AUTOSAR XML (schema 00044)
package /SwComponentType
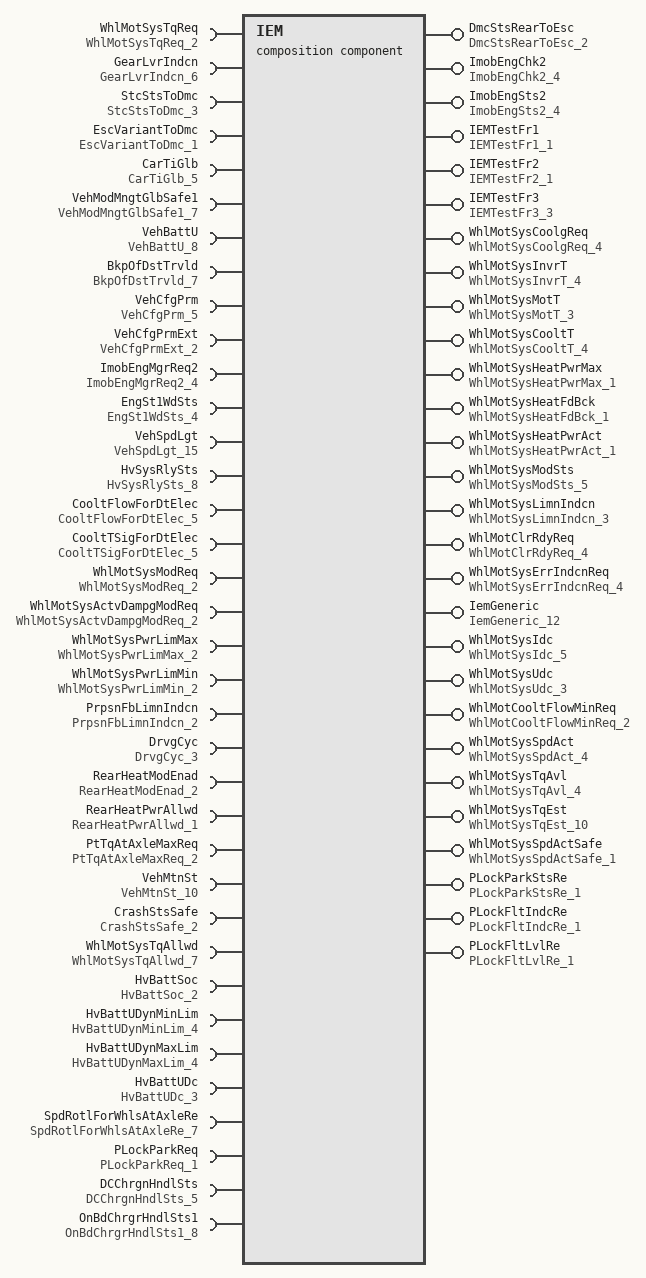
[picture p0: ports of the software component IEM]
  composition sw component type IEM
    28 x provide port:
      DmcStsRearToEsc: nonqueued-sender-com-spec{data-element=DmcStsRearToEsc, uses-end-to-end-protection=true, init-value=constant-reference=DmcStsRearToEsc_2}, provided-interface=DmcStsRearToEsc_2
      ImobEngChk2: nonqueued-sender-com-spec{data-element=ImobEngChk2, init-value=constant-reference=ImobEngChk2_4}, provided-interface=ImobEngChk2_4
      ImobEngSts2: nonqueued-sender-com-spec{data-element=ImobEngSts2, init-value=constant-reference=ImobEngSts2_4}, provided-interface=ImobEngSts2_4
      IEMTestFr1: nonqueued-sender-com-spec{data-element=IEMTestFr1, init-value=constant-reference=IEMTestFr1_1}, provided-interface=IEMTestFr1_1
      IEMTestFr2: nonqueued-sender-com-spec{data-element=IEMTestFr2, init-value=constant-reference=IEMTestFr2_1}, provided-interface=IEMTestFr2_1
      IEMTestFr3: nonqueued-sender-com-spec{data-element=IEMTestFr3, init-value=constant-reference=IEMTestFr3_3}, provided-interface=IEMTestFr3_3
      WhlMotSysCoolgReq: nonqueued-sender-com-spec{data-element=WhlMotSysCoolgReq, init-value=constant-reference=WhlMotSysCoolgReq_4}, provided-interface=WhlMotSysCoolgReq_4
      WhlMotSysInvrT: nonqueued-sender-com-spec{data-element=WhlMotSysInvrT, init-value=constant-reference=WhlMotSysInvrT_4}, provided-interface=WhlMotSysInvrT_4
      WhlMotSysMotT: nonqueued-sender-com-spec{data-element=WhlMotSysMotT, init-value=constant-reference=WhlMotSysMotT_3}, provided-interface=WhlMotSysMotT_3
      WhlMotSysCooltT: nonqueued-sender-com-spec{data-element=WhlMotSysCooltT, init-value=constant-reference=WhlMotSysCooltT_4}, provided-interface=WhlMotSysCooltT_4
      WhlMotSysHeatPwrMax: nonqueued-sender-com-spec{data-element=WhlMotSysHeatPwrMax, init-value=constant-reference=WhlMotSysHeatPwrMax_1}, provided-interface=WhlMotSysHeatPwrMax_1
      WhlMotSysHeatFdBck: nonqueued-sender-com-spec{data-element=WhlMotSysHeatFdBck, init-value=constant-reference=WhlMotSysHeatFdBck_1}, provided-interface=WhlMotSysHeatFdBck_1
      WhlMotSysHeatPwrAct: nonqueued-sender-com-spec{data-element=WhlMotSysHeatPwrAct, init-value=constant-reference=WhlMotSysHeatPwrAct_1}, provided-interface=WhlMotSysHeatPwrAct_1
      WhlMotSysModSts: nonqueued-sender-com-spec{data-element=WhlMotSysModSts, init-value=constant-reference=WhlMotSysModSts_5}, provided-interface=WhlMotSysModSts_5
      WhlMotSysLimnIndcn: nonqueued-sender-com-spec{data-element=WhlMotSysLimnIndcn, init-value=constant-reference=WhlMotSysLimnIndcn_3}, provided-interface=WhlMotSysLimnIndcn_3
      WhlMotClrRdyReq: nonqueued-sender-com-spec{data-element=WhlMotClrRdyReq, init-value=constant-reference=WhlMotClrRdyReq_4}, provided-interface=WhlMotClrRdyReq_4
      WhlMotSysErrIndcnReq: nonqueued-sender-com-spec{data-element=WhlMotSysErrIndcnReq, init-value=constant-reference=WhlMotSysErrIndcnReq_4}, provided-interface=WhlMotSysErrIndcnReq_4
      IemGeneric: nonqueued-sender-com-spec{data-element=IemGeneric, init-value=constant-reference=IemGeneric_12}, provided-interface=IemGeneric_12
      WhlMotSysIdc: nonqueued-sender-com-spec{data-element=WhlMotSysIdc, init-value=constant-reference=WhlMotSysIdc_5}, provided-interface=WhlMotSysIdc_5
      WhlMotSysUdc: nonqueued-sender-com-spec{data-element=WhlMotSysUdc, init-value=constant-reference=WhlMotSysUdc_3}, provided-interface=WhlMotSysUdc_3
      WhlMotCooltFlowMinReq: nonqueued-sender-com-spec{data-element=WhlMotCooltFlowMinReq, init-value=constant-reference=WhlMotCooltFlowMinReq_2}, provided-interface=WhlMotCooltFlowMinReq_2
      WhlMotSysSpdAct: nonqueued-sender-com-spec{data-element=WhlMotSysSpdAct, init-value=constant-reference=WhlMotSysSpdAct_4}, provided-interface=WhlMotSysSpdAct_4
      WhlMotSysTqAvl: nonqueued-sender-com-spec{data-element=WhlMotSysTqAvl, init-value=constant-reference=WhlMotSysTqAvl_4}, provided-interface=WhlMotSysTqAvl_4
      WhlMotSysTqEst: nonqueued-sender-com-spec{data-element=WhlMotSysTqEst, uses-end-to-end-protection=true, init-value=constant-reference=WhlMotSysTqEst_10}, provided-interface=WhlMotSysTqEst_10
      WhlMotSysSpdActSafe: nonqueued-sender-com-spec{data-element=WhlMotSysSpdActSafe, uses-end-to-end-protection=true, init-value=constant-reference=WhlMotSysSpdActSafe_1}, provided-interface=WhlMotSysSpdActSafe_1
      PLockParkStsRe: nonqueued-sender-com-spec{data-element=PLockParkStsRe, init-value=constant-reference=PLockParkStsRe_1}, provided-interface=PLockParkStsRe_1
      PLockFltIndcRe: nonqueued-sender-com-spec{data-element=PLockFltIndcRe, init-value=constant-reference=PLockFltIndcRe_1}, provided-interface=PLockFltIndcRe_1
      PLockFltLvlRe: nonqueued-sender-com-spec{data-element=PLockFltLvlRe, init-value=constant-reference=PLockFltLvlRe_1}, provided-interface=PLockFltLvlRe_1
    36 x require port:
      WhlMotSysTqReq: nonqueued-receiver-com-spec{data-element=WhlMotSysTqReq, alive-timeout=0.5, init-value=constant-reference=WhlMotSysTqReq_2}, required-interface=WhlMotSysTqReq_2
      GearLvrIndcn: nonqueued-receiver-com-spec{data-element=GearLvrIndcn, init-value=constant-reference=GearLvrIndcn_6}, required-interface=GearLvrIndcn_6
      StcStsToDmc: nonqueued-receiver-com-spec{data-element=StcStsToDmc, uses-end-to-end-protection=true, init-value=constant-reference=StcStsToDmc_3}, required-interface=StcStsToDmc_3
      EscVariantToDmc: nonqueued-receiver-com-spec{data-element=EscVariantToDmc, uses-end-to-end-protection=true, init-value=constant-reference=EscVariantToDmc_1}, required-interface=EscVariantToDmc_1
      CarTiGlb: nonqueued-receiver-com-spec{data-element=CarTiGlb, init-value=constant-reference=CarTiGlb_5}, required-interface=CarTiGlb_5
      VehModMngtGlbSafe1: nonqueued-receiver-com-spec{data-element=VehModMngtGlbSafe1, init-value=constant-reference=VehModMngtGlbSafe1_7}, required-interface=VehModMngtGlbSafe1_7
      VehBattU: nonqueued-receiver-com-spec{data-element=VehBattU, init-value=constant-reference=VehBattU_8}, required-interface=VehBattU_8
      BkpOfDstTrvld: nonqueued-receiver-com-spec{data-element=BkpOfDstTrvld, init-value=constant-reference=BkpOfDstTrvld_7}, required-interface=BkpOfDstTrvld_7
      VehCfgPrm: nonqueued-receiver-com-spec{data-element=VehCfgPrm, init-value=constant-reference=VehCfgPrm_5}, required-interface=VehCfgPrm_5
      VehCfgPrmExt: nonqueued-receiver-com-spec{data-element=VehCfgPrmExt, init-value=constant-reference=VehCfgPrmExt_2}, required-interface=VehCfgPrmExt_2
      ImobEngMgrReq2: nonqueued-receiver-com-spec{data-element=ImobEngMgrReq2, init-value=constant-reference=ImobEngMgrReq2_4}, required-interface=ImobEngMgrReq2_4
      EngSt1WdSts: nonqueued-receiver-com-spec{data-element=EngSt1WdSts, init-value=constant-reference=EngSt1WdSts_4}, required-interface=EngSt1WdSts_4
      VehSpdLgt: nonqueued-receiver-com-spec{data-element=VehSpdLgt, uses-end-to-end-protection=true, init-value=constant-reference=VehSpdLgt_15}, required-interface=VehSpdLgt_15
      HvSysRlySts: nonqueued-receiver-com-spec{data-element=HvSysRlySts, uses-end-to-end-protection=true, alive-timeout=0.35, init-value=constant-reference=HvSysRlySts_8}, required-interface=HvSysRlySts_8
      CooltFlowForDtElec: nonqueued-receiver-com-spec{data-element=CooltFlowForDtElec, init-value=constant-reference=CooltFlowForDtElec_5}, required-interface=CooltFlowForDtElec_5
      CooltTSigForDtElec: nonqueued-receiver-com-spec{data-element=CooltTSigForDtElec, init-value=constant-reference=CooltTSigForDtElec_5}, required-interface=CooltTSigForDtElec_5
      WhlMotSysModReq: nonqueued-receiver-com-spec{data-element=WhlMotSysModReq, alive-timeout=0.5, init-value=constant-reference=WhlMotSysModReq_2}, required-interface=WhlMotSysModReq_2
      WhlMotSysActvDampgModReq: nonqueued-receiver-com-spec{data-element=WhlMotSysActvDampgModReq, init-value=constant-reference=WhlMotSysActvDampgModReq_2}, required-interface=WhlMotSysActvDampgModReq_2
      WhlMotSysPwrLimMax: nonqueued-receiver-com-spec{data-element=WhlMotSysPwrLimMax, init-value=constant-reference=WhlMotSysPwrLimMax_2}, required-interface=WhlMotSysPwrLimMax_2
      WhlMotSysPwrLimMin: nonqueued-receiver-com-spec{data-element=WhlMotSysPwrLimMin, init-value=constant-reference=WhlMotSysPwrLimMin_2}, required-interface=WhlMotSysPwrLimMin_2
      PrpsnFbLimnIndcn: nonqueued-receiver-com-spec{data-element=PrpsnFbLimnIndcn, init-value=constant-reference=PrpsnFbLimnIndcn_2}, required-interface=PrpsnFbLimnIndcn_2
      DrvgCyc: nonqueued-receiver-com-spec{data-element=DrvgCyc, init-value=constant-reference=DrvgCyc_3}, required-interface=DrvgCyc_3
      RearHeatModEnad: nonqueued-receiver-com-spec{data-element=RearHeatModEnad, init-value=constant-reference=RearHeatModEnad_2}, required-interface=RearHeatModEnad_2
      RearHeatPwrAllwd: nonqueued-receiver-com-spec{data-element=RearHeatPwrAllwd, init-value=constant-reference=RearHeatPwrAllwd_1}, required-interface=RearHeatPwrAllwd_1
      PtTqAtAxleMaxReq: nonqueued-receiver-com-spec{data-element=PtTqAtAxleMaxReq, alive-timeout=0.5, init-value=constant-reference=PtTqAtAxleMaxReq_2}, required-interface=PtTqAtAxleMaxReq_2
      VehMtnSt: nonqueued-receiver-com-spec{data-element=VehMtnSt, uses-end-to-end-protection=true, init-value=constant-reference=VehMtnSt_10}, required-interface=VehMtnSt_10
      CrashStsSafe: nonqueued-receiver-com-spec{data-element=CrashStsSafe, uses-end-to-end-protection=true, alive-timeout=1, init-value=constant-reference=CrashStsSafe_2}, required-interface=CrashStsSafe_2
      WhlMotSysTqAllwd: nonqueued-receiver-com-spec{data-element=WhlMotSysTqAllwd, uses-end-to-end-protection=true, alive-timeout=0.5, init-value=constant-reference=WhlMotSysTqAllwd_7}, required-interface=WhlMotSysTqAllwd_7
      HvBattSoc: nonqueued-receiver-com-spec{data-element=HvBattSoc, init-value=constant-reference=HvBattSoc_2}, required-interface=HvBattSoc_2
      HvBattUDynMinLim: nonqueued-receiver-com-spec{data-element=HvBattUDynMinLim, init-value=constant-reference=HvBattUDynMinLim_4}, required-interface=HvBattUDynMinLim_4
      HvBattUDynMaxLim: nonqueued-receiver-com-spec{data-element=HvBattUDynMaxLim, init-value=constant-reference=HvBattUDynMaxLim_4}, required-interface=HvBattUDynMaxLim_4
      HvBattUDc: nonqueued-receiver-com-spec{data-element=HvBattUDc, init-value=constant-reference=HvBattUDc_3}, required-interface=HvBattUDc_3
      SpdRotlForWhlsAtAxleRe: nonqueued-receiver-com-spec{data-element=SpdRotlForWhlsAtAxleRe, init-value=constant-reference=SpdRotlForWhlsAtAxleRe_7}, required-interface=SpdRotlForWhlsAtAxleRe_7
      PLockParkReq: nonqueued-receiver-com-spec{data-element=PLockParkReq, init-value=constant-reference=PLockParkReq_1}, required-interface=PLockParkReq_1
      DCChrgnHndlSts: nonqueued-receiver-com-spec{data-element=DCChrgnHndlSts, init-value=constant-reference=DCChrgnHndlSts_5}, required-interface=DCChrgnHndlSts_5
      OnBdChrgrHndlSts1: nonqueued-receiver-com-spec{data-element=OnBdChrgrHndlSts1, init-value=constant-reference=OnBdChrgrHndlSts1_8}, required-interface=OnBdChrgrHndlSts1_8
    13 x port group, all with category=PARTIAL_NETWORKING:
      PropulsionStart
        outer-ports:
          ImobEngChk2
          ImobEngSts2
          WhlMotSysInvrT
          WhlMotSysMotT
          WhlMotSysCooltT
          WhlMotSysHeatPwrMax
          WhlMotSysHeatPwrAct
          WhlMotSysModSts
          WhlMotSysLimnIndcn
          WhlMotClrRdyReq
          WhlMotSysErrIndcnReq
          IemGeneric
          WhlMotSysIdc
          WhlMotSysUdc
          WhlMotSysSpdAct
          WhlMotSysTqAvl
          WhlMotSysTqEst
          PLockParkStsRe
          PLockFltIndcRe
          PLockFltLvlRe
          ImobEngMgrReq2
          EngSt1WdSts
          WhlMotSysModReq
          WhlMotSysActvDampgModReq
          WhlMotSysPwrLimMax
          WhlMotSysPwrLimMin
          PrpsnFbLimnIndcn
          DrvgCyc
          DCChrgnHndlSts
          OnBdChrgrHndlSts1
          HvSysRlySts
          WhlMotSysTqAllwd
          GearLvrIndcn
          HvBattSoc
          HvBattUDynMinLim
          HvBattUDynMaxLim
          HvBattUDc
          WhlMotSysTqReq
          PLockParkReq
      Immobilizer
        outer-ports:
          ImobEngChk2
          ImobEngSts2
          WhlMotSysHeatPwrMax
          WhlMotSysHeatPwrAct
          WhlMotSysModSts
          IemGeneric
          WhlMotSysIdc
          WhlMotSysUdc
          WhlMotSysSpdAct
          ImobEngMgrReq2
          EngSt1WdSts
          WhlMotSysModReq
          WhlMotSysActvDampgModReq
          WhlMotSysPwrLimMax
          WhlMotSysPwrLimMin
          VehMtnSt
          WhlMotSysTqAllwd
          GearLvrIndcn
          VehSpdLgt
          WhlMotSysTqReq
          SpdRotlForWhlsAtAxleRe
      Diagnostics
        outer-ports:
          ImobEngChk2
          ImobEngSts2
          WhlMotSysCoolgReq
          WhlMotSysInvrT
          WhlMotSysMotT
          WhlMotSysCooltT
          WhlMotSysHeatPwrMax
          WhlMotSysHeatFdBck
          WhlMotSysHeatPwrAct
          WhlMotSysModSts
          WhlMotSysLimnIndcn
          WhlMotClrRdyReq
          WhlMotSysErrIndcnReq
          IemGeneric
          WhlMotSysIdc
          WhlMotSysUdc
          WhlMotCooltFlowMinReq
          WhlMotSysSpdAct
          WhlMotSysTqAvl
          WhlMotSysTqEst
          WhlMotSysSpdActSafe
          PLockParkStsRe
          PLockFltIndcRe
          PLockFltLvlRe
          ImobEngMgrReq2
          EngSt1WdSts
          VehSpdLgt
          HvSysRlySts
          CooltFlowForDtElec
          CooltTSigForDtElec
          WhlMotSysModReq
          WhlMotSysActvDampgModReq
          WhlMotSysPwrLimMax
          WhlMotSysPwrLimMin
          PrpsnFbLimnIndcn
          DrvgCyc
          RearHeatModEnad
          RearHeatPwrAllwd
          DCChrgnHndlSts
          OnBdChrgrHndlSts1
          PtTqAtAxleMaxReq
          VehMtnSt
          CrashStsSafe
          WhlMotSysTqAllwd
          GearLvrIndcn
          HvBattSoc
          HvBattUDynMinLim
          HvBattUDynMaxLim
          HvBattUDc
          WhlMotSysTqReq
          SpdRotlForWhlsAtAxleRe
          PLockParkReq
      VehicleModeManagement
        outer-ports:
          ImobEngChk2
          ImobEngSts2
          WhlMotSysCoolgReq
          WhlMotSysInvrT
          WhlMotSysMotT
          WhlMotSysCooltT
          WhlMotSysHeatPwrMax
          WhlMotSysHeatFdBck
          WhlMotSysHeatPwrAct
          WhlMotSysModSts
          WhlMotSysLimnIndcn
          WhlMotClrRdyReq
          WhlMotSysErrIndcnReq
          IemGeneric
          WhlMotSysIdc
          WhlMotSysUdc
          WhlMotCooltFlowMinReq
          WhlMotSysSpdAct
          WhlMotSysTqAvl
          WhlMotSysTqEst
          WhlMotSysSpdActSafe
          PLockParkStsRe
          PLockFltIndcRe
          PLockFltLvlRe
          ImobEngMgrReq2
          EngSt1WdSts
          VehSpdLgt
          HvSysRlySts
          CooltFlowForDtElec
          CooltTSigForDtElec
          WhlMotSysModReq
          WhlMotSysActvDampgModReq
          WhlMotSysPwrLimMax
          WhlMotSysPwrLimMin
          PrpsnFbLimnIndcn
          DrvgCyc
          RearHeatModEnad
          RearHeatPwrAllwd
          DCChrgnHndlSts
          OnBdChrgrHndlSts1
          PtTqAtAxleMaxReq
          VehMtnSt
          CrashStsSafe
          WhlMotSysTqAllwd
          GearLvrIndcn
          HvBattSoc
          HvBattUDynMinLim
          HvBattUDynMaxLim
          HvBattUDc
          WhlMotSysTqReq
          SpdRotlForWhlsAtAxleRe
          PLockParkReq
      ChargingHV
        outer-ports:
          WhlMotSysInvrT
          WhlMotSysMotT
          WhlMotSysCooltT
          WhlMotSysHeatPwrMax
          WhlMotSysHeatPwrAct
          WhlMotSysModSts
          WhlMotSysLimnIndcn
          WhlMotSysErrIndcnReq
          IemGeneric
          WhlMotSysIdc
          WhlMotSysUdc
          WhlMotSysSpdAct
          WhlMotSysTqAvl
          WhlMotSysTqEst
          WhlMotSysSpdActSafe
          PLockParkStsRe
          PLockFltIndcRe
          PLockFltLvlRe
          WhlMotSysModReq
          WhlMotSysActvDampgModReq
          WhlMotSysPwrLimMax
          WhlMotSysPwrLimMin
          PrpsnFbLimnIndcn
          DrvgCyc
          DCChrgnHndlSts
          OnBdChrgrHndlSts1
          HvSysRlySts
          EngSt1WdSts
          WhlMotSysTqAllwd
          GearLvrIndcn
          HvBattSoc
          HvBattUDynMinLim
          HvBattUDynMaxLim
          HvBattUDc
          WhlMotSysTqReq
          PLockParkReq
      ParkingDrivingClimatization
        outer-ports:
          WhlMotSysCoolgReq
          WhlMotSysInvrT
          WhlMotSysMotT
          WhlMotSysCooltT
          WhlMotSysHeatPwrMax
          WhlMotSysHeatFdBck
          WhlMotSysHeatPwrAct
          WhlMotSysModSts
          WhlMotSysLimnIndcn
          WhlMotClrRdyReq
          WhlMotSysErrIndcnReq
          IemGeneric
          WhlMotSysIdc
          WhlMotSysUdc
          WhlMotCooltFlowMinReq
          WhlMotSysSpdAct
          WhlMotSysTqAvl
          WhlMotSysTqEst
          CooltFlowForDtElec
          CooltTSigForDtElec
          WhlMotSysModReq
          WhlMotSysActvDampgModReq
          WhlMotSysPwrLimMax
          WhlMotSysPwrLimMin
          PrpsnFbLimnIndcn
          DrvgCyc
          RearHeatModEnad
          RearHeatPwrAllwd
          DCChrgnHndlSts
          OnBdChrgrHndlSts1
          HvSysRlySts
          EngSt1WdSts
          VehMtnSt
          CrashStsSafe
          WhlMotSysTqAllwd
          GearLvrIndcn
          HvBattSoc
          VehSpdLgt
          HvBattUDynMinLim
          HvBattUDynMaxLim
          HvBattUDc
          WhlMotSysTqReq
          SpdRotlForWhlsAtAxleRe
      TelematicsConnectivity
        outer-ports:
          WhlMotSysInvrT
          WhlMotSysMotT
          WhlMotSysCooltT
          WhlMotSysModSts
          WhlMotSysLimnIndcn
          IemGeneric
          WhlMotSysIdc
          WhlMotSysUdc
          WhlMotSysSpdAct
          WhlMotSysTqEst
          OnBdChrgrHndlSts1
      VehicleDriving
        outer-ports:
          WhlMotSysCoolgReq
          WhlMotSysInvrT
          WhlMotSysMotT
          WhlMotSysCooltT
          WhlMotSysHeatPwrMax
          WhlMotSysHeatFdBck
          WhlMotSysHeatPwrAct
          WhlMotSysModSts
          WhlMotSysLimnIndcn
          WhlMotClrRdyReq
          WhlMotSysErrIndcnReq
          IemGeneric
          WhlMotSysIdc
          WhlMotSysUdc
          WhlMotCooltFlowMinReq
          WhlMotSysSpdAct
          WhlMotSysTqAvl
          WhlMotSysTqEst
          WhlMotSysSpdActSafe
          PLockParkStsRe
          PLockFltIndcRe
          PLockFltLvlRe
          CooltFlowForDtElec
          CooltTSigForDtElec
          WhlMotSysModReq
          WhlMotSysActvDampgModReq
          WhlMotSysPwrLimMax
          WhlMotSysPwrLimMin
          PrpsnFbLimnIndcn
          DrvgCyc
          RearHeatModEnad
          RearHeatPwrAllwd
          DCChrgnHndlSts
          OnBdChrgrHndlSts1
          PtTqAtAxleMaxReq
          HvSysRlySts
          EngSt1WdSts
          VehMtnSt
          CrashStsSafe
          WhlMotSysTqAllwd
          GearLvrIndcn
          HvBattSoc
          VehSpdLgt
          HvBattUDynMinLim
          HvBattUDynMaxLim
          HvBattUDc
          WhlMotSysTqReq
          SpdRotlForWhlsAtAxleRe
          PLockParkReq
      GlobalShortDuration
        outer-ports:
          WhlMotSysCooltT
          WhlMotSysModSts
          WhlMotSysLimnIndcn
          WhlMotSysUdc
          WhlMotSysSpdAct
          WhlMotSysSpdActSafe
          DCChrgnHndlSts
          OnBdChrgrHndlSts1
          HvSysRlySts
          VehMtnSt
          CrashStsSafe
          HvBattSoc
          VehSpdLgt
          HvBattUDynMinLim
          HvBattUDynMaxLim
          HvBattUDc
          SpdRotlForWhlsAtAxleRe
      HVEnergyStorage
        outer-ports:
          WhlMotSysCoolgReq
          WhlMotSysInvrT
          WhlMotSysMotT
          WhlMotSysCooltT
          WhlMotSysModSts
          WhlMotSysLimnIndcn
          WhlMotSysIdc
          WhlMotSysUdc
          WhlMotCooltFlowMinReq
          CooltFlowForDtElec
          CooltTSigForDtElec
          PrpsnFbLimnIndcn
          DCChrgnHndlSts
          HvSysRlySts
          HvBattSoc
          HvBattUDynMinLim
          HvBattUDynMaxLim
          HvBattUDc
      Crash
        outer-ports:
          WhlMotSysCoolgReq
          WhlMotSysInvrT
          WhlMotSysMotT
          WhlMotSysCooltT
          WhlMotSysModSts
          WhlMotSysLimnIndcn
          WhlMotClrRdyReq
          WhlMotSysErrIndcnReq
          WhlMotSysIdc
          WhlMotSysUdc
          WhlMotCooltFlowMinReq
          WhlMotSysSpdAct
          WhlMotSysTqEst
          WhlMotSysSpdActSafe
          CooltFlowForDtElec
          DrvgCyc
          DCChrgnHndlSts
          PtTqAtAxleMaxReq
          HvSysRlySts
          CrashStsSafe
          HvBattSoc
          HvBattUDynMinLim
          HvBattUDynMaxLim
          HvBattUDc
      InfotainmentPush: outer-ports=[WhlMotSysIdc, WhlMotSysUdc, WhlMotSysSpdAct, WhlMotSysTqEst, WhlMotSysSpdActSafe]
      Brake: outer-ports=[WhlMotSysIdc, WhlMotSysUdc, WhlMotSysSpdAct, WhlMotSysTqEst, WhlMotSysSpdActSafe]
    component IEMDTCS: type=IEMDTCS
    component IEMHOST: type=IEMHOST
    delegate IEMDTCS.DmcStsRearToEsc <-> outer port DmcStsRearToEsc
    delegate IEMHOST.ImobEngChk2 <-> outer port ImobEngChk2
    delegate IEMHOST.ImobEngSts2 <-> outer port ImobEngSts2
    delegate IEMHOST.IEMTestFr{1..3} <-> outer port IEMTestFr{1..3}
    delegate IEMHOST.WhlMotSysCoolgReq <-> outer port WhlMotSysCoolgReq
    delegate IEMHOST.WhlMotSysInvrT <-> outer port WhlMotSysInvrT
    delegate IEMHOST.WhlMotSysMotT <-> outer port WhlMotSysMotT
    delegate IEMHOST.WhlMotSysCooltT <-> outer port WhlMotSysCooltT
    delegate IEMHOST.WhlMotSysHeatPwrMax <-> outer port WhlMotSysHeatPwrMax
    delegate IEMHOST.WhlMotSysHeatFdBck <-> outer port WhlMotSysHeatFdBck
    delegate IEMHOST.WhlMotSysHeatPwrAct <-> outer port WhlMotSysHeatPwrAct
    delegate IEMHOST.WhlMotSysModSts <-> outer port WhlMotSysModSts
    delegate IEMHOST.WhlMotSysLimnIndcn <-> outer port WhlMotSysLimnIndcn
    delegate IEMHOST.WhlMotClrRdyReq <-> outer port WhlMotClrRdyReq
    delegate IEMHOST.WhlMotSysErrIndcnReq <-> outer port WhlMotSysErrIndcnReq
    delegate IEMHOST.IemGeneric <-> outer port IemGeneric
    delegate IEMHOST.WhlMotSysIdc <-> outer port WhlMotSysIdc
    delegate IEMHOST.WhlMotSysUdc <-> outer port WhlMotSysUdc
    delegate IEMHOST.WhlMotCooltFlowMinReq <-> outer port WhlMotCooltFlowMinReq
    delegate IEMHOST.WhlMotSysSpdAct <-> outer port WhlMotSysSpdAct
    delegate IEMHOST.WhlMotSysTqAvl <-> outer port WhlMotSysTqAvl
    delegate IEMHOST.WhlMotSysTqEst <-> outer port WhlMotSysTqEst
    delegate IEMHOST.WhlMotSysSpdActSafe <-> outer port WhlMotSysSpdActSafe
    delegate IEMHOST.PLockParkStsRe <-> outer port PLockParkStsRe
    delegate IEMHOST.PLockFltIndcRe <-> outer port PLockFltIndcRe
    delegate IEMHOST.PLockFltLvlRe <-> outer port PLockFltLvlRe
    delegate IEMDTCS.WhlMotSysTqReq <-> outer port WhlMotSysTqReq
    delegate IEMHOST.WhlMotSysTqReq <-> outer port WhlMotSysTqReq
    delegate IEMDTCS.GearLvrIndcn <-> outer port GearLvrIndcn
    delegate IEMHOST.GearLvrIndcn <-> outer port GearLvrIndcn
    delegate IEMDTCS.StcStsToDmc <-> outer port StcStsToDmc
    delegate IEMDTCS.EscVariantToDmc <-> outer port EscVariantToDmc
    delegate IEMHOST.CarTiGlb <-> outer port CarTiGlb
    delegate IEMHOST.VehModMngtGlbSafe1 <-> outer port VehModMngtGlbSafe1
    delegate IEMHOST.VehBattU <-> outer port VehBattU
    delegate IEMHOST.BkpOfDstTrvld <-> outer port BkpOfDstTrvld
    delegate IEMHOST.VehCfgPrm <-> outer port VehCfgPrm
    delegate IEMHOST.VehCfgPrmExt <-> outer port VehCfgPrmExt
    delegate IEMHOST.ImobEngMgrReq2 <-> outer port ImobEngMgrReq2
    delegate IEMHOST.EngSt1WdSts <-> outer port EngSt1WdSts
    delegate IEMHOST.VehSpdLgt <-> outer port VehSpdLgt
    delegate IEMHOST.HvSysRlySts <-> outer port HvSysRlySts
    delegate IEMHOST.CooltFlowForDtElec <-> outer port CooltFlowForDtElec
    delegate IEMHOST.CooltTSigForDtElec <-> outer port CooltTSigForDtElec
    delegate IEMHOST.WhlMotSysModReq <-> outer port WhlMotSysModReq
    delegate IEMHOST.WhlMotSysActvDampgModReq <-> outer port WhlMotSysActvDampgModReq
    delegate IEMHOST.WhlMotSysPwrLimMax <-> outer port WhlMotSysPwrLimMax
    delegate IEMHOST.WhlMotSysPwrLimMin <-> outer port WhlMotSysPwrLimMin
    delegate IEMHOST.PrpsnFbLimnIndcn <-> outer port PrpsnFbLimnIndcn
    delegate IEMHOST.DrvgCyc <-> outer port DrvgCyc
    delegate IEMHOST.RearHeatModEnad <-> outer port RearHeatModEnad
    delegate IEMHOST.RearHeatPwrAllwd <-> outer port RearHeatPwrAllwd
    delegate IEMHOST.PtTqAtAxleMaxReq <-> outer port PtTqAtAxleMaxReq
    delegate IEMHOST.VehMtnSt <-> outer port VehMtnSt
    delegate IEMHOST.CrashStsSafe <-> outer port CrashStsSafe
    delegate IEMHOST.WhlMotSysTqAllwd <-> outer port WhlMotSysTqAllwd
    delegate IEMHOST.HvBattSoc <-> outer port HvBattSoc
    delegate IEMHOST.HvBattUDynMinLim <-> outer port HvBattUDynMinLim
    delegate IEMHOST.HvBattUDynMaxLim <-> outer port HvBattUDynMaxLim
    delegate IEMHOST.HvBattUDc <-> outer port HvBattUDc
    delegate IEMHOST.SpdRotlForWhlsAtAxleRe <-> outer port SpdRotlForWhlsAtAxleRe
    delegate IEMHOST.PLockParkReq <-> outer port PLockParkReq
    delegate IEMHOST.DCChrgnHndlSts <-> outer port DCChrgnHndlSts
    delegate IEMHOST.OnBdChrgrHndlSts1 <-> outer port OnBdChrgrHndlSts1
    connect IEMHOST.WhlMotSysSpdActSafe -> IEMDTCS.WhlMotSysSpdActSafe
